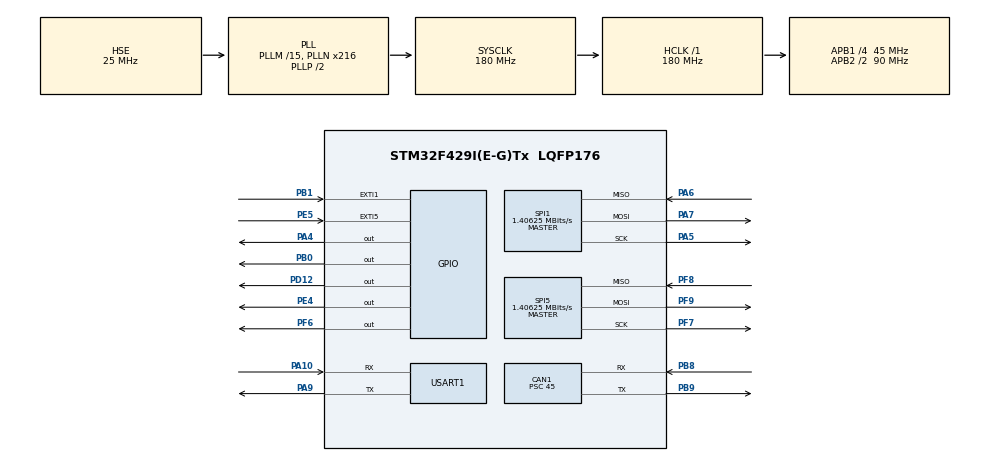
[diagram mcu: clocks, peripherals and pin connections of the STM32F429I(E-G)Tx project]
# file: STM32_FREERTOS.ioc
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CAN1.ABOM=ENABLE
CAN1.AWUM=ENABLE
CAN1.BS1=CAN_BS1_4TQ
CAN1.BS2=CAN_BS2_5TQ
CAN1.CalculateTimeBit=10000
CAN1.CalculateTimeQuantum=1000.0
CAN1.Prescaler=45
Dma.Request0=USART1_TX
Dma.USART1_TX.0.Direction=DMA_MEMORY_TO_PERIPH
Dma.USART1_TX.0.FIFOMode=DMA_FIFOMODE_DISABLE
Dma.USART1_TX.0.Instance=DMA2_Stream7
Dma.USART1_TX.0.MemDataAlignment=DMA_MDATAALIGN_BYTE
Dma.USART1_TX.0.MemInc=DMA_MINC_ENABLE
Dma.USART1_TX.0.Mode=DMA_NORMAL
Dma.USART1_TX.0.PeriphDataAlignment=DMA_PDATAALIGN_BYTE
Dma.USART1_TX.0.PeriphInc=DMA_PINC_DISABLE
Dma.USART1_TX.0.Priority=DMA_PRIORITY_LOW
FREERTOS.Tasks01=defaultTask,0,128,StartDefaultTask,Default,NULL
Mcu.Family=STM32F4
Mcu.Name=STM32F429I(E-G)Tx
Mcu.Package=LQFP176
NVIC.CAN1_RX0_IRQn=true\:5\:0\:true\:false\:true\:true\:true
NVIC.CAN1_RX1_IRQn=true\:6\:0\:true\:false\:true\:true\:true
NVIC.DMA2_Stream7_IRQn=true\:5\:0\:false\:false\:true\:true\:false
NVIC.EXTI1_IRQn=true\:15\:0\:true\:false\:true\:true\:true
NVIC.EXTI9_5_IRQn=true\:13\:0\:true\:false\:true\:true\:true
NVIC.PriorityGroup=NVIC_PRIORITYGROUP_4
NVIC.TIM2_IRQn=true\:0\:0\:false\:false\:true\:false\:false
NVIC.TimeBase=TIM2_IRQn
NVIC.TimeBaseIP=TIM2
NVIC.USART1_IRQn=true\:12\:0\:true\:false\:true\:true\:true
PA10.Mode=Asynchronous
PA10.Signal=USART1_RX
PA13.Mode=Serial_Wire
PA13.Signal=SYS_JTMS-SWDIO
PA14.Mode=Serial_Wire
PA14.Signal=SYS_JTCK-SWCLK
PA4.Signal=GPIO_Output
PA5.Mode=Full_Duplex_Master
PA5.Signal=SPI1_SCK
PA6.Mode=Full_Duplex_Master
PA6.Signal=SPI1_MISO
PA7.Mode=Full_Duplex_Master
PA7.Signal=SPI1_MOSI
PA9.Mode=Asynchronous
PA9.Signal=USART1_TX
PB0.Signal=GPIO_Output
PB1.GPIO_ModeDefaultEXTI=GPIO_MODE_IT_FALLING
PB1.GPIO_PuPd=GPIO_PULLUP
PB1.Signal=GPXTI1
PB8.Mode=Master
PB8.Signal=CAN1_RX
PB9.Mode=Master
PB9.Signal=CAN1_TX
PD12.Signal=GPIO_Output
PE4.Signal=GPIO_Output
PE5.Signal=GPXTI5
PF6.Signal=GPIO_Output
PF7.Mode=Full_Duplex_Master
PF7.Signal=SPI5_SCK
PF8.Mode=Full_Duplex_Master
PF8.Signal=SPI5_MISO
PF9.Mode=Full_Duplex_Master
PF9.Signal=SPI5_MOSI
PH0/OSC_IN.Mode=HSE-External-Oscillator
PH0/OSC_IN.Signal=RCC_OSC_IN
PH1/OSC_OUT.Mode=HSE-External-Oscillator
PH1/OSC_OUT.Signal=RCC_OSC_OUT
ProjectManager.HeapSize=0xF000
ProjectManager.StackSize=0x800
ProjectManager.TargetToolchain=MDK-ARM V5
RCC.48MHZClocksFreq_Value=90000000
RCC.AHBFreq_Value=180000000
RCC.APB1CLKDivider=RCC_HCLK_DIV4
RCC.APB1Freq_Value=45000000
RCC.APB1TimFreq_Value=90000000
RCC.APB2CLKDivider=RCC_HCLK_DIV2
RCC.APB2Freq_Value=90000000
RCC.APB2TimFreq_Value=180000000
RCC.CortexFreq_Value=180000000
RCC.HCLKFreq_Value=180000000
RCC.HSE_VALUE=25000000
RCC.HSI_VALUE=16000000
RCC.LSE_VALUE=32768
RCC.PLLM=15
RCC.PLLN=216
RCC.PLLSourceVirtual=RCC_PLLSOURCE_HSE
RCC.SYSCLKFreq_VALUE=180000000
RCC.SYSCLKSource=RCC_SYSCLKSOURCE_PLLCLK
RCC.VCOOutputFreq_Value=360000000
SPI1.BaudRatePrescaler=SPI_BAUDRATEPRESCALER_64
SPI1.CalculateBaudRate=1.40625 MBits/s
SPI1.Direction=SPI_DIRECTION_2LINES
SPI1.Mode=SPI_MODE_MASTER
SPI1.VirtualType=VM_MASTER
SPI5.BaudRatePrescaler=SPI_BAUDRATEPRESCALER_64
SPI5.CalculateBaudRate=1.40625 MBits/s
SPI5.Direction=SPI_DIRECTION_2LINES
SPI5.Mode=SPI_MODE_MASTER
SPI5.VirtualType=VM_MASTER
USART1.VirtualMode=VM_ASYNC
VP_FREERTOS_VS_ENABLE.Mode=Enabled
VP_SYS_VS_tim2.Mode=TIM2
VP_TIM3_VS_ClockSourceINT.Mode=Internal
board=STM32_FREERTOS

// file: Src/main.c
/**
  ******************************************************************************
  * File Name          : main.c
  * Description        : Main program body
  ******************************************************************************
  * This notice applies to any and all portions of this file
  * that are not between comment pairs USER CODE BEGIN and
  * USER CODE END. Other portions of this file, whether
  * inserted by the user or by software development tools
  * are owned by their respective copyright owners.
  *
  * Copyright (c) 2017 STMicroelectronics International N.V.
  * All rights reserved.
  *
  * Redistribution and use in source and binary forms, with or without
  * modification, are permitted, provided that the following conditions are met:
  *
  * 1. Redistribution of source code must retain the above copyright notice,
  *    this list of conditions and the following disclaimer.
  * 2. Redistributions in binary form must reproduce the above copyright notice,
  *    this list of conditions and the following disclaimer in the documentation
  *    and/or other materials provided with the distribution.
  * 3. Neither the name of STMicroelectronics nor the names of other
  *    contributors to this software may be used to endorse or promote products
  *    derived from this software without specific written permission.
  * 4. This software, including modifications and/or derivative works of this
  *    software, must execute solely and exclusively on microcontroller or
  *    microprocessor devices manufactured by or for STMicroelectronics.
  * 5. Redistribution and use of this software other than as permitted under
  *    this license is void and will automatically terminate your rights under
  *    this license.
  *
  * THIS SOFTWARE IS PROVIDED BY STMICROELECTRONICS AND CONTRIBUTORS "AS IS"
  * AND ANY EXPRESS, IMPLIED OR STATUTORY WARRANTIES, INCLUDING, BUT NOT
  * LIMITED TO, THE IMPLIED WARRANTIES OF MERCHANTABILITY, FITNESS FOR A
  * PARTICULAR PURPOSE AND NON-INFRINGEMENT OF THIRD PARTY INTELLECTUAL PROPERTY
  * RIGHTS ARE DISCLAIMED TO THE FULLEST EXTENT PERMITTED BY LAW. IN NO EVENT
  * SHALL STMICROELECTRONICS OR CONTRIBUTORS BE LIABLE FOR ANY DIRECT, INDIRECT,
  * INCIDENTAL, SPECIAL, EXEMPLARY, OR CONSEQUENTIAL DAMAGES (INCLUDING, BUT NOT
  * LIMITED TO, PROCUREMENT OF SUBSTITUTE GOODS OR SERVICES; LOSS OF USE, DATA,
  * OR PROFITS; OR BUSINESS INTERRUPTION) HOWEVER CAUSED AND ON ANY THEORY OF
  * LIABILITY, WHETHER IN CONTRACT, STRICT LIABILITY, OR TORT (INCLUDING
  * NEGLIGENCE OR OTHERWISE) ARISING IN ANY WAY OUT OF THE USE OF THIS SOFTWARE,
  * EVEN IF ADVISED OF THE POSSIBILITY OF SUCH DAMAGE.
  *
  ******************************************************************************
  */

#include "main.h"
#include "stm32f4xx_hal.h"
#include "cmsis_os.h"
#include "can.h"
#include "dma.h"
#include "spi.h"
#include "tim.h"
#include "usart.h"
#include "gpio.h"

/* USER CODE BEGIN Includes */
#include "bsp_task.h"
#include "bsp_event.h"
#include "bsp_config.h"
/* USER CODE END Includes */

/* USER CODE BEGIN PV */
/* Private variables ---------------------------------------------------------*/

/* USER CODE END PV */

void SystemClock_Config(void);
void MX_FREERTOS_Init(void);

/* USER CODE BEGIN PFP */
/* Private function prototypes -----------------------------------------------*/

/* USER CODE END PFP */

int main(void)
{

  /* MCU Configuration----------------------------------------------------------*/

  /* Reset of all peripherals, Initializes the Flash interface and the Systick. */
  HAL_Init();

  /* Configure the system clock */
  SystemClock_Config();

  /* Initialize all configured peripherals */
  MX_GPIO_Init();
  MX_DMA_Init();
  MX_CAN1_Init();
  MX_TIM3_Init();
  MX_USART1_UART_Init();
  MX_SPI5_Init();
  MX_SPI1_Init();

  /* USER CODE BEGIN 2 */
	InitConfigTable(&Board);
	Bsp_UartInit();
	NetWorkModuleInit(&W5500_Conifg);
	Event_Init(&Event_obj);  //初始化事件管理器

	CanInit(&Bsp_Can_obj,&hcan1);//初始化CAN
	xTaskCreate(LedTask_Func,"Led Task",LED_TASK_STK_SIZE,NULL,LED_TASK_PRIO,LedTask_Handler);
	xTaskCreate(NetWorkTask_Func,"NetWork Task",NETWORK_TASK_STK_SIZE,NULL,NETWORK_TASK_PRIO,NetWorkTask_Handler);
	xTaskCreate(UartTask_Func,"Uart Task",UART_TASK_STK_SIZE,NULL,UART_TASK_PRIO,UartTask_Handler);
	xTaskCreate(CanTask_Func,"Can Task server",CAN_TASK_STK_SIZE,NULL,CAN_TASK_PRIO,CanTask_Handler);
	xTaskCreate(ProcessData_Func,"ProcessData Task",PROCESSDATA_TASK_STK_SIZE,NULL,PROCESSDATA_TASK_PRIO,ProcessDataTask_Handler);
  /* USER CODE END 2 */

  /* Call init function for freertos objects (in freertos.c) */
  MX_FREERTOS_Init();

  /* Start scheduler */
  osKernelStart();

  /* We should never get here as control is now taken by the scheduler */

  /* Infinite loop */
  while (1)
  {

  }

}

/** System Clock Configuration
*/
void SystemClock_Config(void)
{

  RCC_OscInitTypeDef RCC_OscInitStruct;
  RCC_ClkInitTypeDef RCC_ClkInitStruct;

    /**Configure the main internal regulator output voltage
    */
  __HAL_RCC_PWR_CLK_ENABLE();

  __HAL_PWR_VOLTAGESCALING_CONFIG(PWR_REGULATOR_VOLTAGE_SCALE1);

    /**Initializes the CPU, AHB and APB busses clocks
    */
  RCC_OscInitStruct.OscillatorType = RCC_OSCILLATORTYPE_HSE;
  RCC_OscInitStruct.HSEState = RCC_HSE_ON;
  RCC_OscInitStruct.PLL.PLLState = RCC_PLL_ON;
  RCC_OscInitStruct.PLL.PLLSource = RCC_PLLSOURCE_HSE;
  RCC_OscInitStruct.PLL.PLLM = 15;
  RCC_OscInitStruct.PLL.PLLN = 216;
  RCC_OscInitStruct.PLL.PLLP = RCC_PLLP_DIV2;
  RCC_OscInitStruct.PLL.PLLQ = 4;
  if (HAL_RCC_OscConfig(&RCC_OscInitStruct) != HAL_OK)
  {
    _Error_Handler(__FILE__, __LINE__);
  }

    /**Activate the Over-Drive mode
    */
  if (HAL_PWREx_EnableOverDrive() != HAL_OK)
  {
    _Error_Handler(__FILE__, __LINE__);
  }

    /**Initializes the CPU, AHB and APB busses clocks
    */
  RCC_ClkInitStruct.ClockType = RCC_CLOCKTYPE_HCLK|RCC_CLOCKTYPE_SYSCLK
                              |RCC_CLOCKTYPE_PCLK1|RCC_CLOCKTYPE_PCLK2;
  RCC_ClkInitStruct.SYSCLKSource = RCC_SYSCLKSOURCE_PLLCLK;
  RCC_ClkInitStruct.AHBCLKDivider = RCC_SYSCLK_DIV1;
  RCC_ClkInitStruct.APB1CLKDivider = RCC_HCLK_DIV4;
  RCC_ClkInitStruct.APB2CLKDivider = RCC_HCLK_DIV2;

  if (HAL_RCC_ClockConfig(&RCC_ClkInitStruct, FLASH_LATENCY_5) != HAL_OK)
  {
    _Error_Handler(__FILE__, __LINE__);
  }

    /**Configure the Systick interrupt time
    */
  HAL_SYSTICK_Config(HAL_RCC_GetHCLKFreq()/1000);

    /**Configure the Systick
    */
  HAL_SYSTICK_CLKSourceConfig(SYSTICK_CLKSOURCE_HCLK);

  /* SysTick_IRQn interrupt configuration */
  HAL_NVIC_SetPriority(SysTick_IRQn, 15, 0);
}

void HAL_TIM_PeriodElapsedCallback(TIM_HandleTypeDef *htim)
{
  if (htim->Instance == TIM2) {
    HAL_IncTick();
  }
}

void _Error_Handler(char * file, int line)
{
  while(1)
  {
  }
}

/************************ (C) COPYRIGHT STMicroelectronics *****END OF FILE****/
